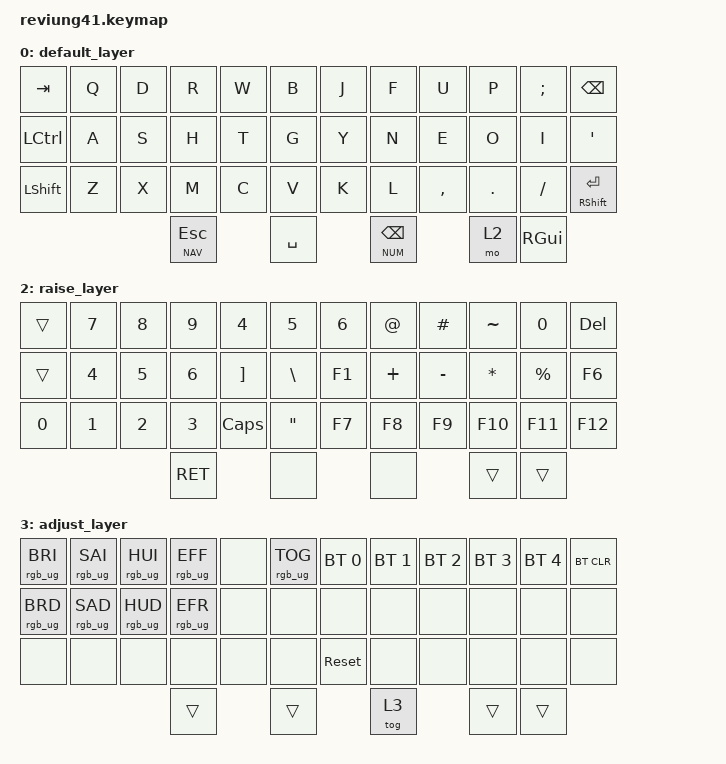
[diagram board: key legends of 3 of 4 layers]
/*
 * Copyright (c) 2020 The ZMK Contributors
 *
 * SPDX-License-Identifier: MIT
 */

#include <behaviors.dtsi>
#include <dt-bindings/zmk/keys.h>
#include <dt-bindings/zmk/bt.h>
#include <dt-bindings/zmk/rgb.h>


#define DEFAULT 0
#define NAV 1
#define NUM 2
#define FKEYS 3

/ {
behaviors { 
     hm: homerow_mods {     
        compatible = "zmk,behavior-hold-tap";
        label = "HOMEROW_MODS";
        #binding-cells = <2>;
        tapping-term-ms = <250>;
        quick-tap-ms = <0>;
        flavor = "tap-preferred";
        bindings = <&kp>, <&kp>;
      };
     hplt: hold_preferred-lt {     
        compatible = "zmk,behavior-hold-tap";
        label = "HOLD_PREFERRED_LT";
        #binding-cells = <2>;
        tapping-term-ms = <195>;
        quick-tap-ms = <0>;
        flavor = "hold-preferred";
        bindings = <&mo>, <&kp>;
      };
     hms: homerow_mod_shift {     
        compatible = "zmk,behavior-hold-tap";
        label = "HOMEROW_MOD_SHIFT";
        #binding-cells = <2>;
        tapping-term-ms = <170>;
        quick-tap-ms = <0>;
        flavor = "balanced";
        bindings = <&kp>, <&kp>;
      };
    };
        keymap {
                compatible = "zmk,keymap";

                default_layer {
// -------------------------------------------------------------------------------------
// |  TAB |  Q  |  W  |  E  |  R  |  T  |   |  Y  |  U   |  I  |  O  |  P  |   BKSP    |
// | CTRL |  A  |  S  |  D  |  F  |  G  |   |  H  |  J   |  K  |  L  |  ;  |    '      |
// | SHFT |  Z  |  X  |  C  |  V  |  B  |   |  N  |  M   |  ,  |  .  |  /  | SHFT(RET) |
//                         | ALT | LWR | SPC | RSE  | ALT |
                        bindings = <
   &kp TAB   &kp Q &kp D &kp R &kp W &kp B   &kp J &kp F  &kp U     &kp P   &kp SEMI    &kp BSPC
   &kp LCTRL &kp A &kp S &kp H &kp T &kp G   &kp Y &kp N  &kp E     &kp O   &kp I       &kp SQT
   &kp LSHFT &kp Z &kp X &kp M &kp C &kp V   &kp K &kp L  &kp COMMA &kp DOT &kp FSLH &mt RSHFT RET
                        &hplt NAV ESC  &kp SPACE &hplt NUM BSPC &mo 2  &kp RGUI
                        >;
                };
zxmcv
                lower_layer {
// ------------------------------------------------------------------------------------
// |    |  !  |  @  |  #  |  $  |  %  |   |  ^  |  &  |  *  |  (  |  )  |      DEL    |
// |    |  _  |  +  |  {  |  }  | "|" |   | LFT | DWN |  UP | RGT |  `  |       ~     |
// |    | ESC | GUI | ALT | CAPS|  "  |   | HOME| END | PGUP| PGDN| PRSC| SHFT(SPACE) |
//                       |     |     | RET | ADJ |     |
                        bindings = <
   &trans &none       &none       &kp UP      &none       &none                              &none       &kp LBKT    &kp RBKT    &kp SQT     &kp GRAVE   &kp DEL
   &trans &kp TAB   &kp LEFT    &kp DOWN    &kp RIGHT   &kp G          &none      &kp GT   &kp EQUAL  &kp RPAR  &kp LPAR  &kp TILDE
   &trans &kp CARET   &kp DLLR    &kp LBRC    &kp RBRC    &none     &tog GAME   &bt BT_CLR   &none       &kp AMPS    &kp EXCL    &kp PIPE    &kp BSLH
 &mt RSHFT SPACE
                                 &trans      &trans       &kp RET        &mo 3       &trans
                        >;
                };

                raise_layer {
// ----------------------------------------------------------------------------
// |    |  1  |  2  |  3  |  4  |  5  |   |  6  |  7  |  8  |  9  |  0  | DEL |
// |    |  -  |  =  |  [  |  ]  |  \  |   | F1  | F2  | F3  | F4  | F5  | F6  |
// |    | ESC | GUI | ALT | CAPS|  "  |   | F7  | F8  | F9  | F10 | F11 | F12 |
//                       |     | ADJ | BKSP |    |     |
                        bindings = <
   &trans &kp N7    &kp N8    &kp N9    &kp N4    &kp N5        &kp N6    &kp AT    &kp HASH    &kp TILDE    &kp N0    &kp DEL
   &trans &kp N4    &kp N5    &kp N6  &kp RBKT  &kp BSLH      &kp F1    &kp PLUS    &kp MINUS    &kp STAR    &kp PRCNT    &kp F6
   &kp N0 &kp N1    &kp N2    &kp N3  &kp CLCK  &kp DQT       &kp F7    &kp F8    &kp F9    &kp F10   &kp F11   &kp F12
                                &RET      &none       &none        &trans      &trans
                        >;
                };

                adjust_layer {
// -----------------------------------------------------------------------------------------
// | RGB BRI+ | RGB SAT+ | RGB HUE+ | RGB ANI+ |    | RGB TOG |   |  BT1  | BT2 | BT3 | BT4 | BT5 | BT CLR |
// | RGB BRI- | RGB SAT- | RGB HUE- | RGB ANI- |    |         |   |       |     |     |     |     |        |
// |          |          |          |          |    |         |   | RESET |     |     |     |     |        |
//                                              |     |     |     |     |     |
                        bindings = <
   &rgb_ug RGB_BRI &rgb_ug RGB_SAI &rgb_ug RGB_HUI &rgb_ug RGB_EFF &none &rgb_ug RGB_TOG    &bt BT_SEL 0 &bt BT_SEL 1 &bt BT_SEL 2 &bt BT_SEL 3 &bt BT_SEL 4 &bt BT_CLR
   &rgb_ug RGB_BRD &rgb_ug RGB_SAD &rgb_ug RGB_HUD &rgb_ug RGB_EFR &none &none              &none        &none        &none        &none        &none        &none
   &none           &none           &none           &none           &none &none              &sys_reset       &none        &none        &none        &none        &none
                                                             &trans      &trans       &tog 3        &trans      &trans
                        >;
                };
        };
};
